# ing920 register map
Vendor: INGChips; Series: ing920xx; File version: 1.0
CPU: CM3 r2p1, little endian, no MPU, no FPU, 2 interrupt priority bits
Registers are 32-bit, read-write, reset 0x0 unless marked. A register's access mark holds for its fields unless they carry their own. Offsets are from the block's base; [hi:lo] are bit positions.

## aon1_ctrl
Base 0x40102000
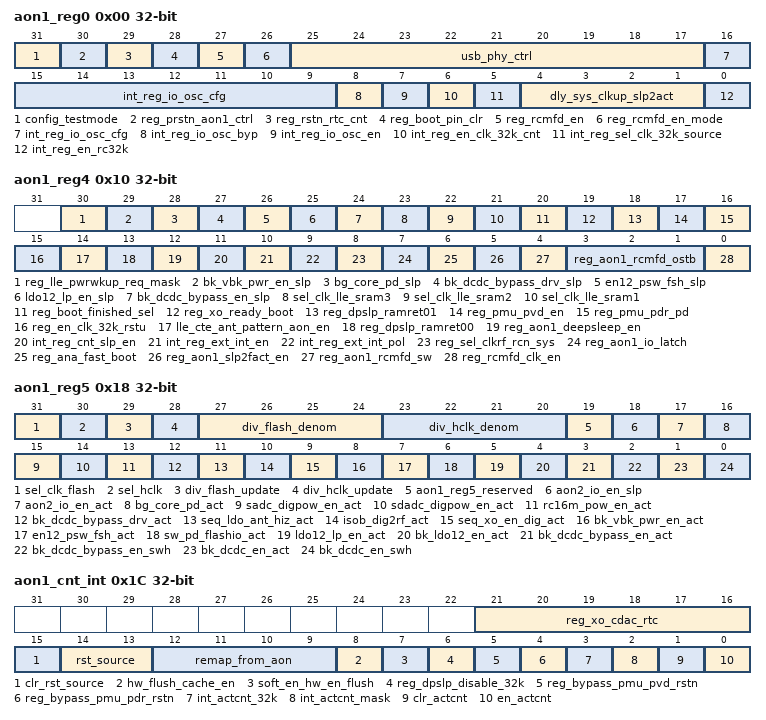
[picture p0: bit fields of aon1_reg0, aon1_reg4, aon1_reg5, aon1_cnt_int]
0x00 aon1_reg0 — reg description:
  [31] config_testmode — reg description:
  [30] reg_prstn_aon1_ctrl — reg description:
  [29] reg_rstn_rtc_cnt — reg description:
  [28] reg_boot_pin_clr — reg description:
  [27] reg_rcmfd_en — reg description:
  [26] reg_rcmfd_en_mode — reg description:
  [25:17] usb_phy_ctrl — reg description:
  [16:9] int_reg_io_osc_cfg — reg description:
  [8] int_reg_io_osc_byp — reg description:
  [7] int_reg_io_osc_en — reg description:
  [6] int_reg_en_clk_32k_cnt — reg description:
  [5] int_reg_sel_clk_32k_source — reg description:
  [4:1] dly_sys_clkup_slp2act — reg description:
  [0] int_reg_en_rc32k — reg description:
0x04 aon1_reg1 — reg description:
  [31:0] int_reg_cnt_tgt
0x10 aon1_reg4 — reg description:
  [30] reg_lle_pwrwkup_req_mask — reg description:
  [29] bk_vbk_pwr_en_slp — reg description:
  [28] bg_core_pd_slp — reg description:
  [27] bk_dcdc_bypass_drv_slp — reg description:
  [26] en12_psw_fsh_slp — reg description:
  [25] ldo12_lp_en_slp — reg description:
  [24] bk_dcdc_bypass_en_slp — reg description:
  [23] sel_clk_lle_sram3 — reg description:
  [22] sel_clk_lle_sram2 — reg description:
  [21] sel_clk_lle_sram1 — reg description:
  [20] reg_boot_finished_sel — reg description:
  [19] reg_xo_ready_boot — reg description:
  [18] reg_dpslp_ramret01 — reg description:
  [17] reg_pmu_pvd_en — reg description:
  [16] reg_pmu_pdr_pd — reg description:
  [15] reg_en_clk_32k_rstu — reg description:
  [14] lle_cte_ant_pattern_aon_en — reg description:
  [13] reg_dpslp_ramret00 — reg description:
  [12] reg_aon1_deepsleep_en — reg description:
  [11] int_reg_cnt_slp_en — reg description:
  [10] int_reg_ext_int_en — reg description:
  [9] int_reg_ext_int_pol — reg description:
  [8] reg_sel_clkrf_rcn_sys — reg description:
  [7] reg_aon1_io_latch — reg description:
  [6] reg_ana_fast_boot — reg description:
  [5] reg_aon1_slp2fact_en — reg description:
  [4] reg_aon1_rcmfd_sw — reg description:
  [3:1] reg_aon1_rcmfd_ostb — reg description:
  [0] reg_rcmfd_clk_en — reg description:
0x14 aon1_boot — reg description:
  [31:0] reg_aon1_boot
0x18 aon1_reg5 — reg description:
  [31] sel_clk_flash — reg description:
  [30] sel_hclk — reg description:
  [29] div_flash_update — reg description:
  [28] div_hclk_update — reg description:
  [27:24] div_flash_denom — reg description:
  [23:20] div_hclk_denom — reg description:
  [19] aon1_reg5_reserved — reg description:
  [18] aon2_io_en_slp — reg description:
  [17] aon2_io_en_act — reg description:
  [16] bg_core_pd_act — reg description:
  [15] sadc_digpow_en_act — reg description:
  [14] sdadc_digpow_en_act — reg description:
  [13] rc16m_pow_en_act — reg description:
  [12] bk_dcdc_bypass_drv_act — reg description:
  [11] seq_ldo_ant_hiz_act — reg description:
  [10] isob_dig2rf_act — reg description:
  [9] seq_xo_en_dig_act — reg description:
  [8] bk_vbk_pwr_en_act — reg description:
  [7] en12_psw_fsh_act — reg description:
  [6] sw_pd_flashio_act — reg description:
  [5] ldo12_lp_en_act — reg description:
  [4] bk_ldo12_en_act — reg description:
  [3] bk_dcdc_bypass_en_act — reg description:
  [2] bk_dcdc_bypass_en_swh — reg description:
  [1] bk_dcdc_en_act — reg description:
  [0] bk_dcdc_en_swh — reg description:
0x1C aon1_cnt_int — reg description:
  [21:16] reg_xo_cdac_rtc — reg description:
  [15] clr_rst_source — reg description:
  [14:13] rst_source — reg description:
  [12:9] remap_from_aon — reg description:
  [8] hw_flush_cache_en — reg description:
  [7] soft_en_hw_en_flush — reg description:
  [6] reg_dpslp_disable_32k — reg description:
  [5] reg_bypass_pmu_pvd_rstn — reg description:
  [4] reg_bypass_pmu_pdr_rstn — reg description:
  [3] int_actcnt_32k — reg description:
  [2] int_actcnt_mask — reg description:
  [1] clr_actcnt — reg description:
  [0] en_actcnt — reg description:
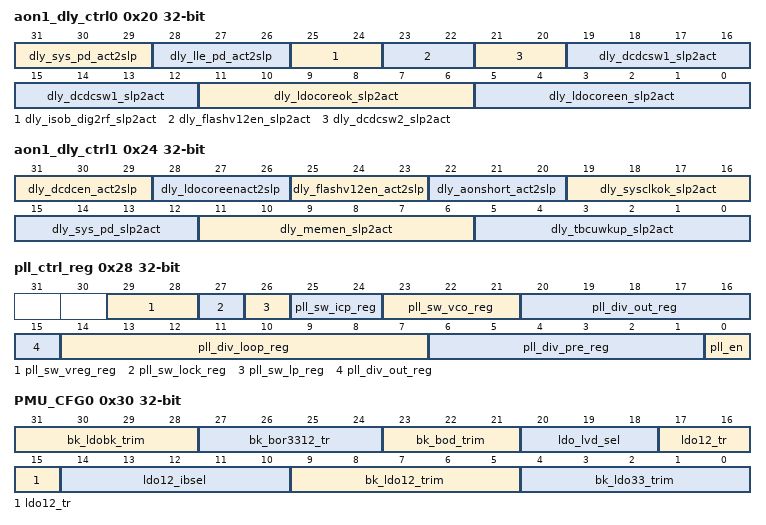
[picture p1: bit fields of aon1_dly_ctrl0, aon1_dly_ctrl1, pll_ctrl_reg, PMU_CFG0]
0x20 aon1_dly_ctrl0 — reg description:
  [31:29] dly_sys_pd_act2slp — reg description:
  [28:26] dly_lle_pd_act2slp — reg description:
  [25:24] dly_isob_dig2rf_slp2act — reg description:
  [23:22] dly_flashv12en_slp2act — reg description:
  [21:20] dly_dcdcsw2_slp2act — reg description:
  [19:12] dly_dcdcsw1_slp2act — reg description:
  [11:6] dly_ldocoreok_slp2act — reg description:
  [5:0] dly_ldocoreen_slp2act — reg description:
0x24 aon1_dly_ctrl1 — reg description:
  [31:29] dly_dcdcen_act2slp — reg description:
  [28:26] dly_ldocoreenact2slp — reg description:
  [25:23] dly_flashv12en_act2slp — reg description:
  [22:20] dly_aonshort_act2slp — reg description:
  [19:16] dly_sysclkok_slp2act — reg description:
  [15:12] dly_sys_pd_slp2act — reg description:
  [11:6] dly_memen_slp2act — reg description:
  [5:0] dly_tbcuwkup_slp2act — reg description:
0x28 pll_ctrl_reg — reg description:
  [29:28] pll_sw_vreg_reg — reg description:
  [27] pll_sw_lock_reg — reg description:
  [26] pll_sw_lp_reg — reg description:
  [25:24] pll_sw_icp_reg — reg description:
  [23:21] pll_sw_vco_reg — reg description:
  [20:15] pll_div_out_reg — reg description:
  [14:7] pll_div_loop_reg — reg description:
  [6:1] pll_div_pre_reg — reg description:
  [0] pll_en — reg description:
0x2C patch_cfg — reg description:
0x30 PMU_CFG0 — reg description:
  [31:28] bk_ldobk_trim — reg description:
  [27:24] bk_bor3312_tr — reg description:
  [23:21] bk_bod_trim — reg description:
  [20:18] ldo_lvd_sel — reg description:
  [17:15] ldo12_tr — reg description:
  [14:10] ldo12_ibsel — reg description:
  [9:5] bk_ldo12_trim — reg description:
  [4:0] bk_ldo33_trim — reg description:
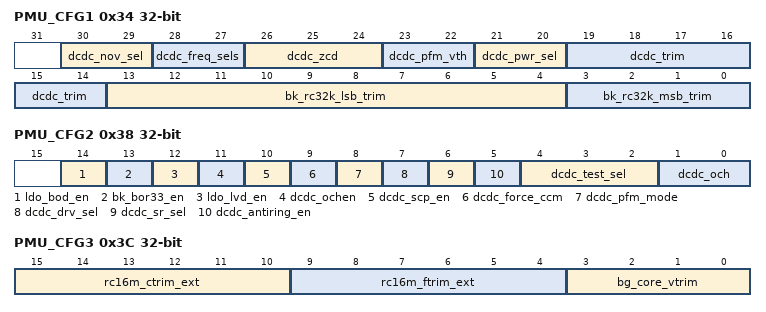
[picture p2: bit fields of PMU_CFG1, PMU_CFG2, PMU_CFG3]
0x34 PMU_CFG1 — reg description:
  [30:29] dcdc_nov_sel — reg description:
  [28:27] dcdc_freq_sels — reg description:
  [26:24] dcdc_zcd — reg description:
  [23:22] dcdc_pfm_vth — reg description:
  [21:20] dcdc_pwr_sel — reg description:
  [19:14] dcdc_trim — reg description:
  [13:4] bk_rc32k_lsb_trim — reg description:
  [3:0] bk_rc32k_msb_trim — reg description:
0x38 PMU_CFG2 — reg description:
  [14] ldo_bod_en — reg description:
  [13] bk_bor33_en — reg description:
  [12] ldo_lvd_en — reg description:
  [11] dcdc_ochen — reg description:
  [10] dcdc_scp_en — reg description:
  [9] dcdc_force_ccm — reg description:
  [8] dcdc_pfm_mode — reg description:
  [7] dcdc_drv_sel — reg description:
  [6] dcdc_sr_sel — reg description:
  [5] dcdc_antiring_en — reg description:
  [4:2] dcdc_test_sel — reg description:
  [1:0] dcdc_och — reg description:
0x3C PMU_CFG3 — reg description:
  [15:10] rc16m_ctrim_ext — reg description:
  [9:4] rc16m_ftrim_ext — reg description:
  [3:0] bg_core_vtrim — reg description:
